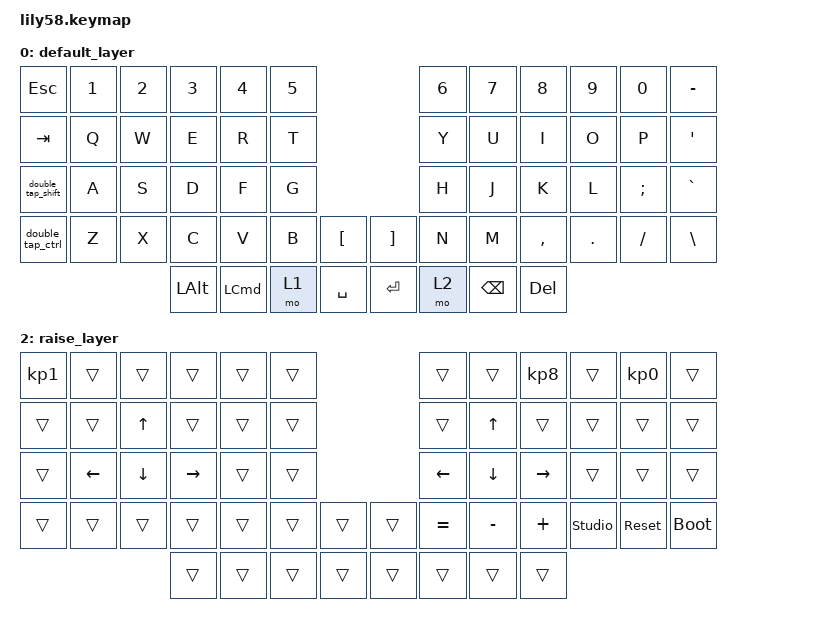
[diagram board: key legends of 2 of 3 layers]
/*
 * Copyright (c) 2020 The ZMK Contributors
 *
 * SPDX-License-Identifier: MIT
 */

#include <behaviors.dtsi>
#include <dt-bindings/zmk/keys.h>

/ {
    macros {
        rs_lc_c_o: rs_lc_c_o {
            compatible = "zmk,behavior-macro";
            #binding-cells = <0>;
            bindings = <&kp RS(LC(C)) &kp O>;
            label = "RS_LC_C_O";
        };
    };

    behaviors {
        double_tap_shift: double_tap_shift {
            compatible = "zmk,behavior-tap-dance";
            label = "DOUBLE_TAP_SHIFT";
            #binding-cells = <0>;
            bindings = <&kp LEFT_SHIFT>, <&kp RIGHT_SHIFT>;
        };

        double_tap_ctrl: double_tap_ctrl {
            compatible = "zmk,behavior-tap-dance";
            label = "DOUBLE_TAP_CTRL";
            #binding-cells = <0>;
            bindings = <&kp LCTRL>, <&kp RCTRL>;
        };
    };

    keymap {
        compatible = "zmk,keymap";

        default_layer {
            // ------------------------------------------------------------------------------------------------------------
            // |  ESC  |  1  |  2  |  3   |  4   |  5   |                   |  6   |  7    |  8    |  9   |   0   |   `   |
            // |  TAB  |  Q  |  W  |  E   |  R   |  T   |                   |  Y   |  U    |  I    |  O   |   P   |   -   |
            // |  CTRL |  A  |  S  |  D   |  F   |  G   |                   |  H   |  J    |  K    |  L   |   ;   |   '   |
            // | SHIFT |  Z  |  X  |  C   |  V   |  B   |   "["  |  |  "]"  |  N   |  M    |  ,    |  .   |   /   | SHIFT |
            //                     | ALT  | GUI  | LOWER|  SPACE |  | ENTER | RAISE| BSPC  | GUI   |

            bindings = <
&kp ESC            &kp N1  &kp N2  &kp N3        &kp N4            &kp N5                          &kp N6  &kp N7         &kp N8      &kp N9   &kp N0    &kp MINUS
&kp TAB            &kp Q   &kp W   &kp E         &kp R             &kp T                           &kp Y   &kp U          &kp I       &kp O    &kp P     &kp SINGLE_QUOTE
&double_tap_shift  &kp A   &kp S   &kp D         &kp F             &kp G                           &kp H   &kp J          &kp K       &kp L    &kp SEMI  &kp GRAVE
&double_tap_ctrl   &kp Z   &kp X   &kp C         &kp V             &kp B   &kp LBKT     &kp RBKT   &kp N   &kp M          &kp COMMA   &kp DOT  &kp FSLH  &kp BACKSLASH
                                   &kp LEFT_ALT  &kp LEFT_COMMAND  &mo 1   &kp SPACE    &kp ENTER  &mo 2   &kp BACKSPACE  &kp DELETE
            >;

            sensor-bindings = <&inc_dec_kp C_VOL_UP C_VOL_DN>;
        };

        lower_layer {
            // ------------------------------------------------------------------------------------------------------------
            // | BTCLR | BT1 | BT2 |  BT3 |  BT4 |  BT5 |                   |      |       |       |      |       |       |
            // |  F1   |  F2 |  F3 |  F4  |  F5  |  F6  |                   |  F7  |  F8   |  F9   |  F10 |  F11  |  F12  |
            // |   `   |  !  |  @  |  #   |  $   |  %   |                   |  ^   |  &    |  *    |  (   |   )   |   ~   |
            // |       |     |     |      |      |      |        |  |       |      |  _    |  +    |  {   |   }   |  "|"  |
            //                     |      |      |      |        |  |       |      |       |       |

            bindings = <
&kp F1       &kp F2      &kp F3          &kp F4  &kp F5  &kp F6                             &kp F7  &kp F8  &kp F9  &kp F10  &kp F11  &kp F12
&rs_lc_c_o   &trans      &trans          &trans  &trans  &trans                             &trans  &trans  &trans  &trans   &trans   &kp RSHFT
&trans       &trans      &trans          &trans  &trans  &trans                             &trans  &trans  &trans  &trans   &trans   &kp RIGHT_CONTROL
&bootloader  &sys_reset  &studio_unlock  &trans  &trans  &trans  &trans             &trans  &trans  &trans  &trans  &trans   &trans   &trans
                                         &trans  &trans  &trans  &kp PRINTSCREEN    &trans  &trans  &trans
            >;

            sensor-bindings = <&inc_dec_kp C_VOL_UP C_VOL_DN>;
        };

        raise_layer {
            // ------------------------------------------------------------------------------------------------------------
            // |       |     |     |      |      |      |                   |      |       |       |      |       |       |
            // |   `   |  1  |  2  |  3   |  4   |  5   |                   |  6   |   7   |   8   |  9   |   0   |       |
            // |   F1  |  F2 |  F3 |  F4  |  F5  |  F6  |                   |      |   <-  |   v   |  ^   |  ->   |       |
            // |   F7  |  F8 |  F9 |  F10 |  F11 |  F12 |        |  |       |  +   |   -   |   =   |  [   |   ]   |   \   |
            //                     |      |      |      |        |  |       |      |       |       |

            bindings = <
&kp KP_NUMBER_1  &trans          &trans          &trans     &trans  &trans                    &trans     &trans        &kp KP_NUMBER_8  &trans          &kp KP_NUMBER_0  &trans
&trans           &trans          &kp UP_ARROW    &trans     &trans  &trans                    &trans     &kp UP_ARROW  &trans           &trans          &trans           &trans
&trans           &kp LEFT_ARROW  &kp DOWN_ARROW  &kp RIGHT  &trans  &trans                    &kp LEFT   &kp DOWN      &kp RIGHT        &trans          &trans           &trans
&trans           &trans          &trans          &trans     &trans  &trans  &trans    &trans  &kp EQUAL  &kp MINUS     &kp PLUS         &studio_unlock  &sys_reset       &bootloader
                                                 &trans     &trans  &trans  &trans    &trans  &trans     &trans        &trans
            >;

            sensor-bindings = <&inc_dec_kp C_VOL_UP C_VOL_DN>;
        };
    };
};
